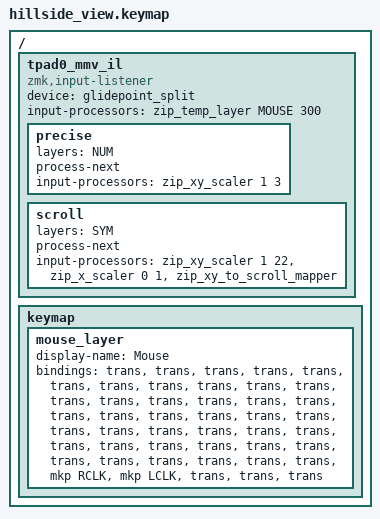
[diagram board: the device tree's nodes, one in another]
#include "hillside_view_common.dtsi"
#include <dt-bindings/zmk/mouse.h>
#include <behaviors/mouse_keys.dtsi>
#include <dt-bindings/zmk/input_transform.h>
#include <dt-bindings/zmk/pointing.h>
#include <input/processors.dtsi>

#define MOUSE 4


/ {
    // Trackpad input listener with temp layer and layer-specific processors
    // - MOUSE layer activates during any trackpad movement (300ms timeout)
    // - NUM layer: precise mode (slower movement)
    // - SYM layer: scroll mode
    tpad0_mmv_il {
        compatible = "zmk,input-listener";
        device = <&glidepoint_split>;
        input-processors = <&zip_temp_layer MOUSE 300>;

        precise {
            layers = <NUM>;
            process-next;
            input-processors = <&zip_xy_scaler 1 3>;
        };

        scroll {
            layers = <SYM>;
            process-next;
            input-processors = <&zip_xy_scaler 1 22>,
                               <&zip_x_scaler 0 1>,
                               <&zip_xy_to_scroll_mapper>;
        };
    };

    keymap {
        mouse_layer {
            display-name = "Mouse";
            bindings = <
    &trans   &trans   &trans   &trans   &trans   &trans       &trans   &trans   &trans   &trans   &trans   &trans
    &trans   &trans   &trans   &trans   &trans   &trans       &trans   &trans   &trans   &trans   &trans   &trans
    &trans   &trans   &trans   &trans   &trans   &trans       &trans   &trans   &trans   &trans   &trans   &trans
                                         &trans                                            &trans
                     &trans   &trans   &trans   &mkp RCLK             &mkp LCLK &trans  &trans   &trans
            >;
        };
    };
};
